# M4L2 register map
File version: 0.1
Registers are 32-bit, read-write, reset 0x0 unless marked. A register's access mark holds for its fields unless they carry their own. Offsets are from the block's base; [hi:lo] are bit positions; {n}, {i} and the like mark numbered series.

## TSPI0 — Serial Interface (TSPI)
Base 0x4006A000
Same registers: TSPI1 0x4006A400, TSPI2 0x4006A800
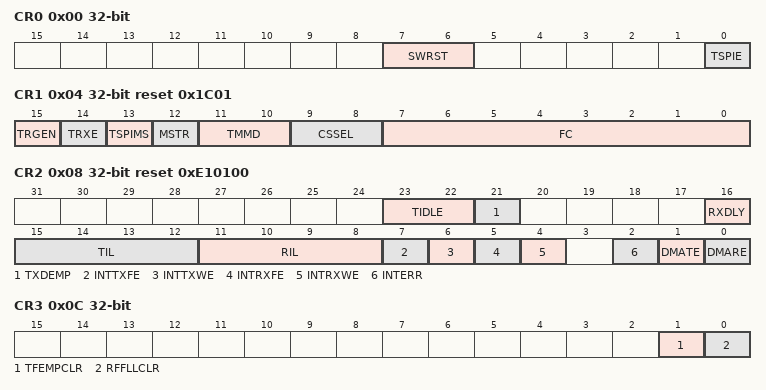
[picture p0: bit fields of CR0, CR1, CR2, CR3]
0x00 CR0 — TSPI Control Register 0
  [7:6] SWRST wo, [0] TSPIE
0x04 CR1 reset 0x1C01 — TSPI Control Register 1
  [15] TRGEN, [14] TRXE, [13] TSPIMS, [12] MSTR, [11:10] TMMD, [9:8] CSSEL, [7:0] FC
0x08 CR2 reset 0xE10100 — TSPI Control Register 2
  [23:22] TIDLE, [21] TXDEMP, [16] RXDLY, [15:12] TIL, [11:8] RIL, [7] INTTXFE, [6] INTTXWE, [5] INTRXFE, [4] INTRXWE, [2] INTERR, [1] DMATE, [0] DMARE
0x0C CR3 — TSPI Control Register 3
  [1] TFEMPCLR wo, [0] RFFLLCLR wo
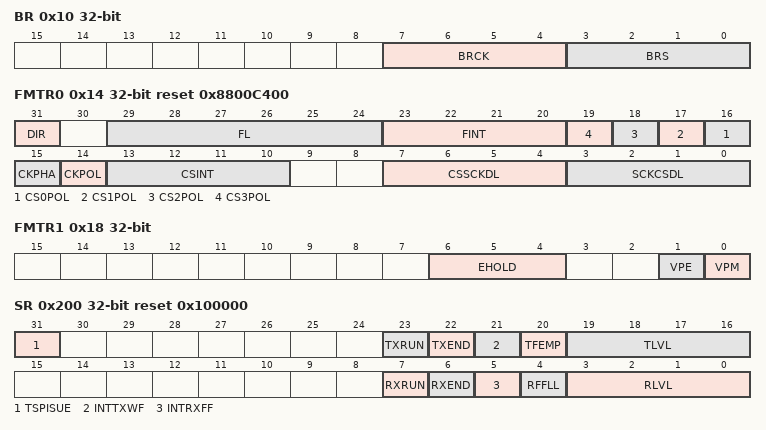
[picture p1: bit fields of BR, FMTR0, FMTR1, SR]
0x10 BR — TSPI Baud Rate Generator Control Register
  [7:4] BRCK, [3:0] BRS
0x14 FMTR0 reset 0x8800C400 — TSPI Format Control Register 0
  [31] DIR, [29:24] FL, [23:20] FINT, [n+16] CS{n}POL (n=0..3), [15] CKPHA, [14] CKPOL, [13:10] CSINT, [7:4] CSSCKDL, [3:0] SCKCSDL
0x18 FMTR1 — TSPI Format Control Register 1
  [6:4] EHOLD, [1] VPE, [0] VPM
0x100 DR — TSPI Data Register
  [31:0] TSPIDR
0x200 SR reset 0x100000 — TSPI Status Register
  [31] TSPISUE ro, [23] TXRUN ro, [22] TXEND, [21] INTTXWF, [20] TFEMP ro, [19:16] TLVL ro, [7] RXRUN ro, [6] RXEND, [5] INTRXFF, [4] RFFLL ro, [3:0] RLVL ro
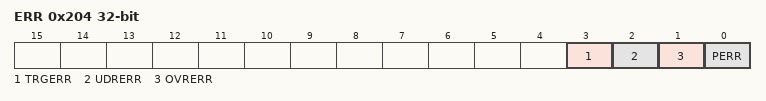
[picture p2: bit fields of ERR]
0x204 ERR — TSPI Parity Error Flag Register
  [3] TRGERR, [2] UDRERR, [1] OVRERR, [0] PERR ro

## CG — Clock Generator (CG)
Base 0x40083000
0x00 PROTECT reset 0xC1
  [7:0] PROTECT
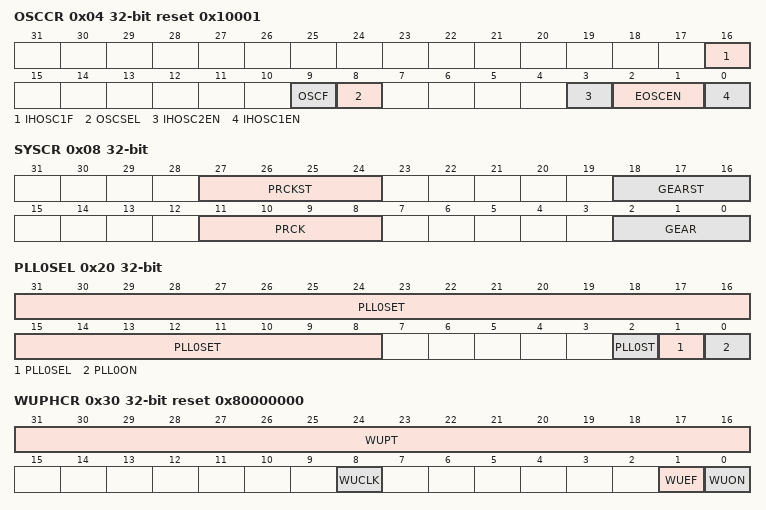
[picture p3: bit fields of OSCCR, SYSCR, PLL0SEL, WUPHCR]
0x04 OSCCR reset 0x10001 — Oscillation Control Register
  [16] IHOSC1F ro, [9] OSCF ro, [8] OSCSEL, [3] IHOSC2EN, [2:1] EOSCEN, [0] IHOSC1EN
0x08 SYSCR — System Clock Control Register
  [27:24] PRCKST ro, [18:16] GEARST ro, [11:8] PRCK, [2:0] GEAR
0x0C STBYCR — Standby Control Register
  [1:0] STBY
0x20 PLL0SEL — PLL Selection Register 0
  [31:8] PLL0SET, [2] PLL0ST ro, [1] PLL0SEL, [0] PLL0ON
0x30 WUPHCR reset 0x80000000 — High OSC Warming-up Register
  [31:16] WUPT, [8] WUCLK, [1] WUEF ro, [0] WUON wo
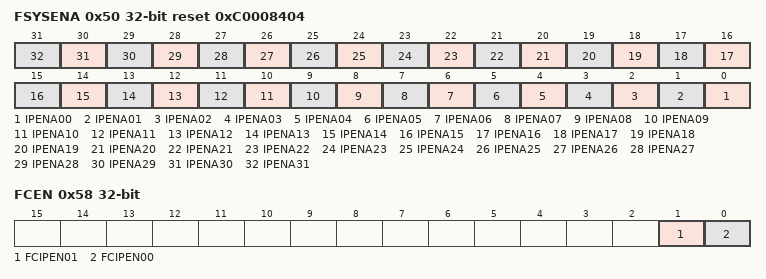
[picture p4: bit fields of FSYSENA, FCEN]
0x50 FSYSENA reset 0xC0008404 — High fsys Supply Stop Register A
  [n] IPENA{n:02} (n=0..31)
0x58 FCEN — FC Supply Stop Register
  [1] FCIPEN01, [0] FCIPEN00
0x5C SPCLKEN — ADC TRACE Clock Supply Stop Register
  [16] ADCKEN

## IB — Interrupt Control B Register
Base 0x40083200
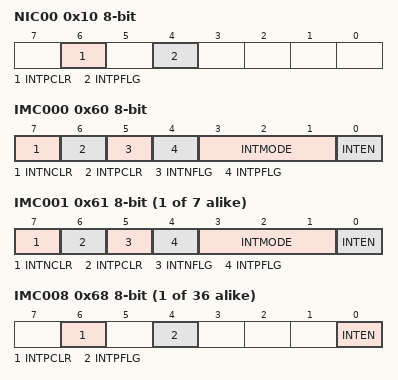
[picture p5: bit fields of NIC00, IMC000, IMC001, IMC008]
0x10 NIC00 8-bit — Non maskable interrupt Control Register 00
  [6] INTPCLR wo, [4] INTPFLG ro
0x60 IMC000 8-bit — interrupt Mode Control Register 000
  [7] INTNCLR wo, [6] INTPCLR wo, [5] INTNFLG ro, [4] INTPFLG ro, [3:1] INTMODE, [0] INTEN
{0x60+i} IMC{i:03} 8-bit (i=1..7) — interrupt Mode Control Register {i:03}
  [7] INTNCLR wo, [6] INTPCLR wo, [5] INTNFLG ro, [4] INTPFLG ro, [3:1] INTMODE ro, [0] INTEN
{0x60+i} IMC{i:03} 8-bit (i=8..43) — interrupt Mode Control Register {i:03}
  [6] INTPCLR wo, [4] INTPFLG ro, [0] INTEN

## IMN — Interrupt Monitor Register
Base 0x40083300
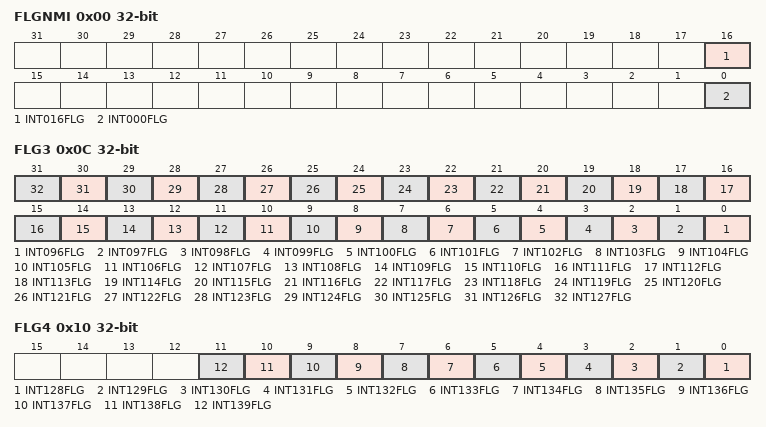
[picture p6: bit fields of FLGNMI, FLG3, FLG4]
0x00 FLGNMI ro — NMI Interrupt Monitor Flag 0
  [16] INT016FLG, [0] INT000FLG
0x0C FLG3 ro — Interrupt Monitor Flag 3 (096 - 127)
  [n-96] INT{n:03}FLG (n=96..127)
0x10 FLG4 ro — Interrupt Monitor Flag 4 (128 - 159)
  [n-128] INT{n}FLG (n=128..139)

## DNF
Base 0x40040200
0x00 CKCR — DNF clock Control register
  [2:0] NFCKS
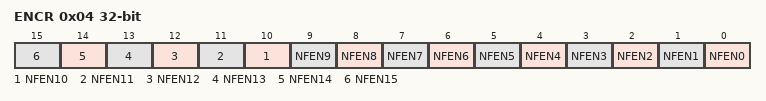
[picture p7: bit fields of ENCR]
0x04 ENCR — DNF Enable register
  [n] NFEN{n} (n=0..15)

## SIWD — Watchdog Timer (WD)
Base 0x40040600
0x00 PRO reset 0x1E — SIWD Protect Register
  [7:0] PROTECT
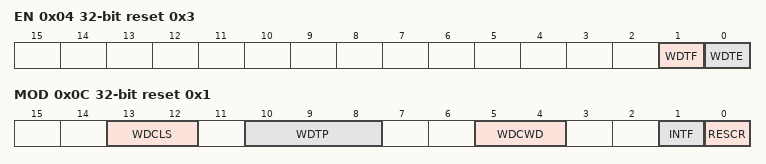
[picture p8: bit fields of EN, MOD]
0x04 EN reset 0x3 — SIWD Enable Register
  [1] WDTF ro, [0] WDTE
0x08 CR wo (reset mask 0xFFFFFF00) — SIWD Control Register
  [7:0] WDCR
0x0C MOD reset 0x1 — SIWD Mode Register
  [13:12] WDCLS, [10:8] WDTP, [5:4] WDCWD, [1] INTF, [0] RESCR
0x10 MONI ro (reset mask 0xC0000000) — SIWD Monitor Register
  [29:0] MONI
0x14 OSCCR — SIWD Oscillation control register
  [0] OSCPRO

## AD — ADC
Base 0x4005A000
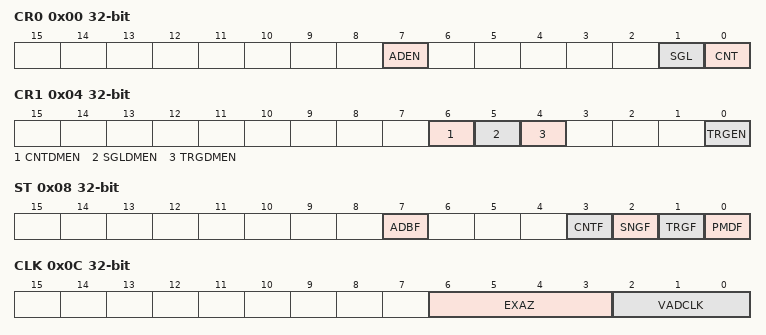
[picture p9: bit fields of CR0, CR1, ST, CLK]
0x00 CR0 — AD Control Register 0
  [7] ADEN, [1] SGL wo, [0] CNT
0x04 CR1 — AD Control Register 1
  [6] CNTDMEN, [5] SGLDMEN, [4] TRGDMEN, [0] TRGEN
0x08 ST ro — AD Status Register
  [7] ADBF, [3] CNTF, [2] SNGF, [1] TRGF, [0] PMDF
0x0C CLK — AD Conversion Clock Setting Register
  [6:3] EXAZ, [2:0] VADCLK
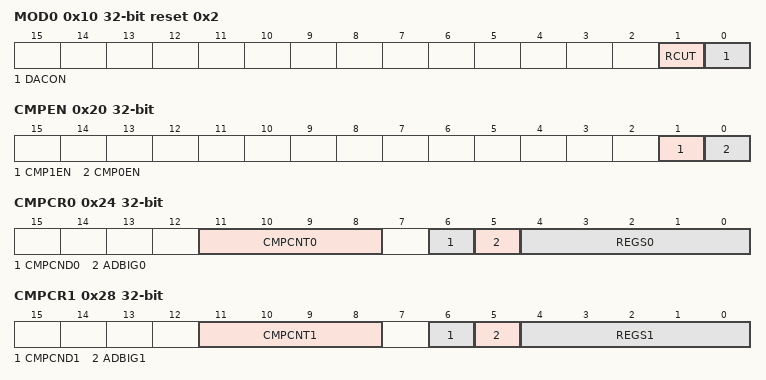
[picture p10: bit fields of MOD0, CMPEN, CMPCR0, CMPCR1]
0x10 MOD0 reset 0x2 — AD Mode Control Register 0
  [1] RCUT, [0] DACON
0x14 MOD1 reset 0x4000 — AD Mode Control Register 1
0x18 MOD2 — AD Mode Control Register 2
0x20 CMPEN — AD Monitor function interrupt permission register
  [1] CMP1EN, [0] CMP0EN
0x24 CMPCR0 — AD Monitor function Setting Register 0
  [11:8] CMPCNT0, [6] CMPCND0, [5] ADBIG0, [4:0] REGS0
0x28 CMPCR1 — AD Monitor function Setting Register 1
  [11:8] CMPCNT1, [6] CMPCND1, [5] ADBIG1, [4:0] REGS1
0x2C CMP0 — AD Conversion Result Comparison Register 0
  [15:4] AD0CMP0
0x30 CMP1 — AD Conversion Result Comparison Register 1
  [15:4] AD0CMP1
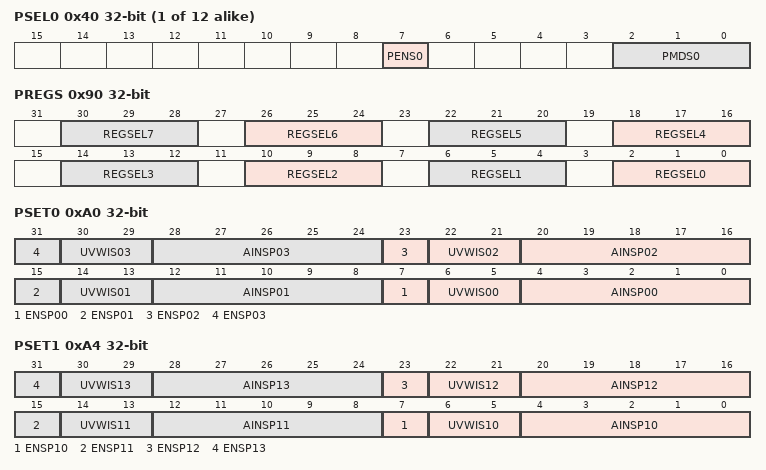
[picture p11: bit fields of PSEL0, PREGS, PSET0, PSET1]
{0x40+4i} PSEL{i} (i=0..11) — AD PMD Trigger Program Number Select Register {i}
  [7] PENS{i}, [2:0] PMDS{i}
{0x70+4i} PINTS{i} (i=0..7) — AD PMD Trigger Interrupt Select Register {i}
  [1:0] INTSEL{i}
0x90 PREGS — AD PMD Trigger Conversion Result Storage Select Register 1
  [4n+2:4n] REGSEL{n} (n=0..7)
0xA0 PSET0 — AD PMD Trigger Program Register 0
  [8n+7] ENSP{n:02} (n=0..3), [8n+6:8n+5] UVWIS{n:02} (n=0..3), [8n+4:8n] AINSP{n:02} (n=0..3)
0xA4 PSET1 — AD PMD Trigger Program Register 1
  [8n-73] ENSP{n} (n=10..13), [8n-74:8n-75] UVWIS{n} (n=10..13), [8n-76:8n-80] AINSP{n} (n=10..13)
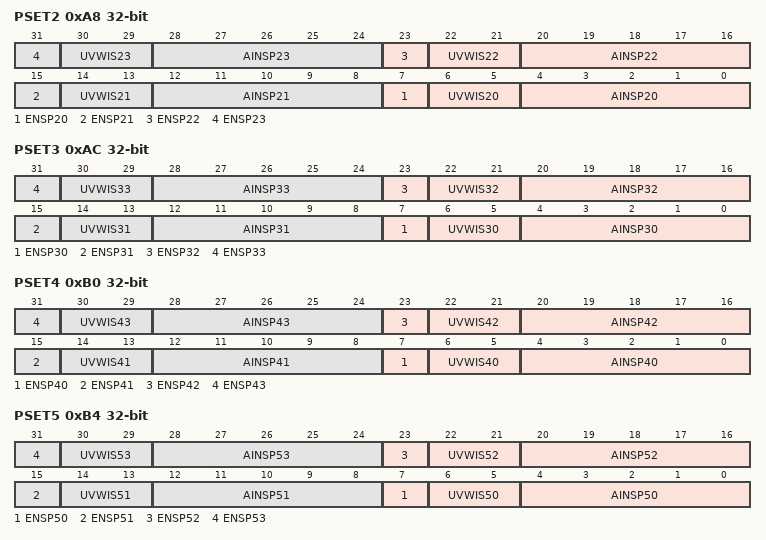
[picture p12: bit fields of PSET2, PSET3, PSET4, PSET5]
0xA8 PSET2 — AD PMD Trigger Program Register 2
  [8n-153] ENSP{n} (n=20..23), [8n-154:8n-155] UVWIS{n} (n=20..23), [8n-156:8n-160] AINSP{n} (n=20..23)
0xAC PSET3 — AD PMD Trigger Program Register 3
  [8n-233] ENSP{n} (n=30..33), [8n-234:8n-235] UVWIS{n} (n=30..33), [8n-236:8n-240] AINSP{n} (n=30..33)
0xB0 PSET4 — AD PMD Trigger Program Register 4
  [8n-313] ENSP{n} (n=40..43), [8n-314:8n-315] UVWIS{n} (n=40..43), [8n-316:8n-320] AINSP{n} (n=40..43)
0xB4 PSET5 — AD PMD Trigger Program Register 5
  [8n-393] ENSP{n} (n=50..53), [8n-394:8n-395] UVWIS{n} (n=50..53), [8n-396:8n-400] AINSP{n} (n=50..53)
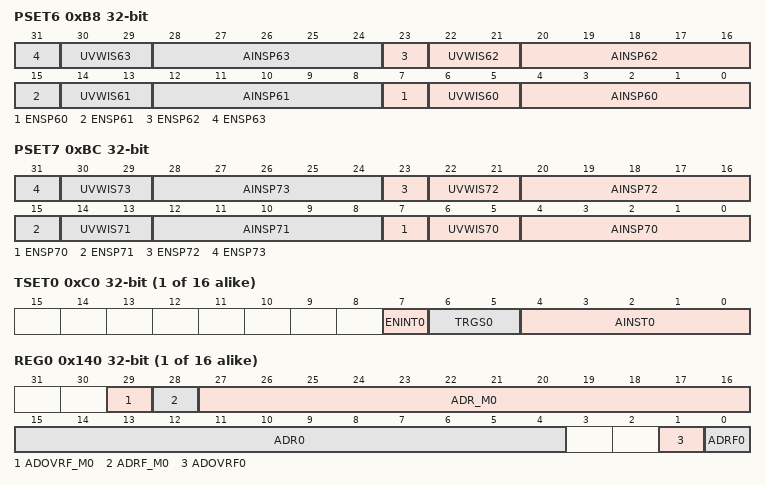
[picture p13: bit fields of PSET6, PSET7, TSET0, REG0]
0xB8 PSET6 — AD PMD Trigger Program Register 6
  [8n-473] ENSP{n} (n=60..63), [8n-474:8n-475] UVWIS{n} (n=60..63), [8n-476:8n-480] AINSP{n} (n=60..63)
0xBC PSET7 — AD PMD Trigger Program Register 7
  [8n-553] ENSP{n} (n=70..73), [8n-554:8n-555] UVWIS{n} (n=70..73), [8n-556:8n-560] AINSP{n} (n=70..73)
{0xC0+4i} TSET{i} (i=0..15) — AD General purpose Trigger Program Register {i}
  [7] ENINT{i}, [6:5] TRGS{i}, [4:0] AINST{i}
{0x140+4i} REG{i} ro (i=0..15) — AD Conversion Result Register {i}
  [29] ADOVRF_M{i}, [28] ADRF_M{i}, [27:16] ADR_M{i}, [15:4] ADR{i}, [1] ADOVRF{i}, [0] ADRF{i}
